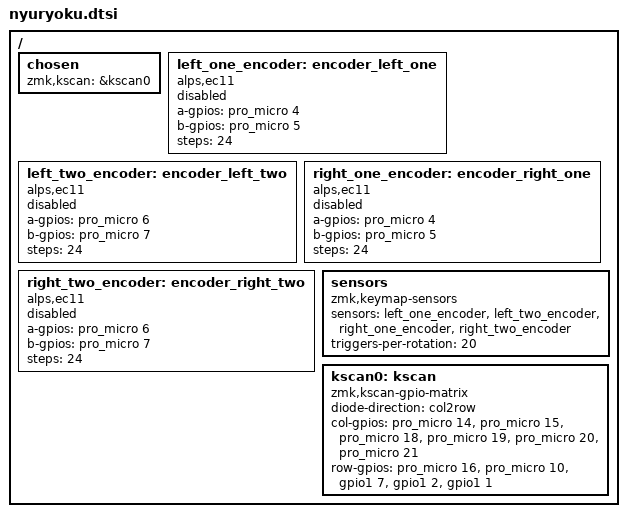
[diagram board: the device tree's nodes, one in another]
#include <dt-bindings/zmk/matrix_transform.h>

/ {
    chosen {
        zmk,kscan = &kscan0;
    };
    left_one_encoder: encoder_left_one {
        compatible = "alps,ec11";
        a-gpios = <&pro_micro 4 (GPIO_ACTIVE_HIGH | GPIO_PULL_UP)>;
        b-gpios = <&pro_micro 5 (GPIO_ACTIVE_HIGH | GPIO_PULL_UP)>;
        steps = <24>;
        #sensor-binding-cells = <2>;
        status = "disabled";
    };
    left_two_encoder: encoder_left_two {
        compatible = "alps,ec11";
        a-gpios = <&pro_micro 6 (GPIO_ACTIVE_HIGH | GPIO_PULL_UP)>;
        b-gpios = <&pro_micro 7 (GPIO_ACTIVE_HIGH | GPIO_PULL_UP)>;
        steps = <24>;
        #sensor-binding-cells = <2>;
        status = "disabled";
    };
    right_one_encoder: encoder_right_one {
        compatible = "alps,ec11";
        a-gpios = <&pro_micro 4 (GPIO_ACTIVE_HIGH | GPIO_PULL_UP)>;
        b-gpios = <&pro_micro 5 (GPIO_ACTIVE_HIGH | GPIO_PULL_UP)>;
        steps = <24>;
        #sensor-binding-cells = <2>;
        status = "disabled";
    };
    right_two_encoder: encoder_right_two {
        compatible = "alps,ec11";
        a-gpios = <&pro_micro 6 (GPIO_ACTIVE_HIGH | GPIO_PULL_UP)>;
        b-gpios = <&pro_micro 7 (GPIO_ACTIVE_HIGH | GPIO_PULL_UP)>;
        steps = <24>;
        #sensor-binding-cells = <2>;
        status = "disabled";
    };
    sensors: sensors {
        compatible = "zmk,keymap-sensors";
        sensors = <&left_one_encoder &left_two_encoder &right_one_encoder &right_two_encoder>;
        triggers-per-rotation = <20>;
    };

    kscan0: kscan {
        compatible = "zmk,kscan-gpio-matrix";
        
        diode-direction = "col2row";
        col-gpios
            = <&pro_micro 14 GPIO_ACTIVE_HIGH>
            , <&pro_micro 15 GPIO_ACTIVE_HIGH>
            , <&pro_micro 18 GPIO_ACTIVE_HIGH>
            , <&pro_micro 19 GPIO_ACTIVE_HIGH>
            , <&pro_micro 20 GPIO_ACTIVE_HIGH>
            , <&pro_micro 21 GPIO_ACTIVE_HIGH>
            ;
        row-gpios
            = <&pro_micro 16 (GPIO_ACTIVE_HIGH | GPIO_PULL_DOWN)>
            , <&pro_micro 10 (GPIO_ACTIVE_HIGH | GPIO_PULL_DOWN)>
            , <&gpio1 7 (GPIO_ACTIVE_HIGH | GPIO_PULL_DOWN)>
            , <&gpio1 2 (GPIO_ACTIVE_HIGH | GPIO_PULL_DOWN)>
            , <&gpio1 1 (GPIO_ACTIVE_HIGH | GPIO_PULL_DOWN)>
            ;

    };
};
